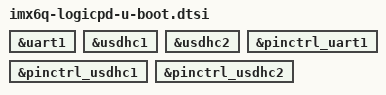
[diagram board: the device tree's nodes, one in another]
// SPDX-License-Identifier: GPL-2.0+
/*
 * Copyright (C) 2019 Logic PD <aford173@gmail.com>
 */

#include "imx6qdl-u-boot.dtsi"

&uart1 {
	bootph-pre-ram;
};

&usdhc1 {
	bootph-pre-ram;
};

&usdhc2 {
	bootph-pre-ram;
};

&pinctrl_uart1 {
	bootph-pre-ram;
};

&pinctrl_usdhc1 {
	bootph-pre-ram;
};

&pinctrl_usdhc2 {
	bootph-pre-ram;
};
